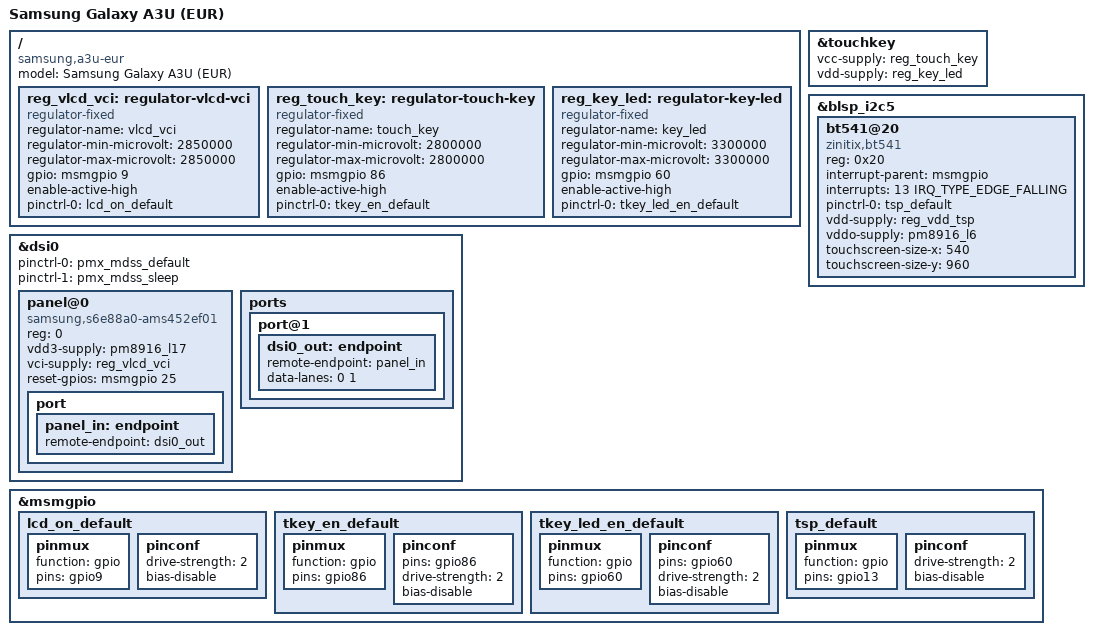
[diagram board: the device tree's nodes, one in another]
// SPDX-License-Identifier: GPL-2.0-only

/dts-v1/;

#include "msm8916-samsung-a2015-common.dtsi"

/ {
	model = "Samsung Galaxy A3U (EUR)";
	compatible = "samsung,a3u-eur", "qcom,msm8916";

	reg_vlcd_vci: regulator-vlcd-vci {
		compatible = "regulator-fixed";
		regulator-name = "vlcd_vci";
		regulator-min-microvolt = <2850000>;
		regulator-max-microvolt = <2850000>;

		gpio = <&msmgpio 9 0>;
		enable-active-high;

		pinctrl-names = "default";
		pinctrl-0 = <&lcd_on_default>;
	};

	reg_touch_key: regulator-touch-key {
		compatible = "regulator-fixed";
		regulator-name = "touch_key";
		regulator-min-microvolt = <2800000>;
		regulator-max-microvolt = <2800000>;

		gpio = <&msmgpio 86 0>;
		enable-active-high;

		pinctrl-names = "default";
		pinctrl-0 = <&tkey_en_default>;
	};

	reg_key_led: regulator-key-led {
		compatible = "regulator-fixed";
		regulator-name = "key_led";
		regulator-min-microvolt = <3300000>;
		regulator-max-microvolt = <3300000>;

		gpio = <&msmgpio 60 0>;
		enable-active-high;

		pinctrl-names = "default";
		pinctrl-0 = <&tkey_led_en_default>;
	};
};

&touchkey {
	vcc-supply = <&reg_touch_key>;
	vdd-supply = <&reg_key_led>;
};

&blsp_i2c5 {
	status = "okay";

	bt541@20 {
		compatible = "zinitix,bt541";
		reg = <0x20>;
		interrupt-parent = <&msmgpio>;
		interrupts = <13 IRQ_TYPE_EDGE_FALLING>;
		pinctrl-names = "default";
		pinctrl-0 = <&tsp_default>;
		vdd-supply = <&reg_vdd_tsp>;
		vddo-supply = <&pm8916_l6>;
		touchscreen-size-x = <540>;
		touchscreen-size-y = <960>;
	};
};

&dsi0 {
	pinctrl-names = "default", "sleep";
	pinctrl-0 = <&pmx_mdss_default>;
	pinctrl-1 = <&pmx_mdss_sleep>;

	panel@0 {
		reg = <0>;

		compatible = "samsung,s6e88a0-ams452ef01";

		vdd3-supply = <&pm8916_l17>;
		vci-supply = <&reg_vlcd_vci>;
		reset-gpios = <&msmgpio 25 GPIO_ACTIVE_HIGH>;

		port {
			panel_in: endpoint {
				remote-endpoint = <&dsi0_out>;
			};
		};
	};

	ports {
		port@1 {
			dsi0_out: endpoint {
				remote-endpoint = <&panel_in>;
				data-lanes = <0 1>;
			};
		};
	};
};

&msmgpio {
	lcd_on_default: lcd_on_default {
		pinmux {
			function = "gpio";
			pins = "gpio9";
		};
		pinconf {
			drive-strength = <2>;
			bias-disable;
		};
	};

	tkey_en_default: tkey_en_default {
		pinmux {
			function = "gpio";
			pins = "gpio86";
		};
		pinconf {
			pins = "gpio86";
			drive-strength = <2>;
			bias-disable;
		};
	};

	tkey_led_en_default: tkey_led_en_default {
		pinmux {
			function = "gpio";
			pins = "gpio60";
		};
		pinconf {
			pins = "gpio60";
			drive-strength = <2>;
			bias-disable;
		};
	};

	tsp_default: tsp_default {
		pinmux {
			function = "gpio";
			pins = "gpio13";
		};
		pinconf {
			drive-strength = <2>;
			bias-disable;
		};
	};
};
